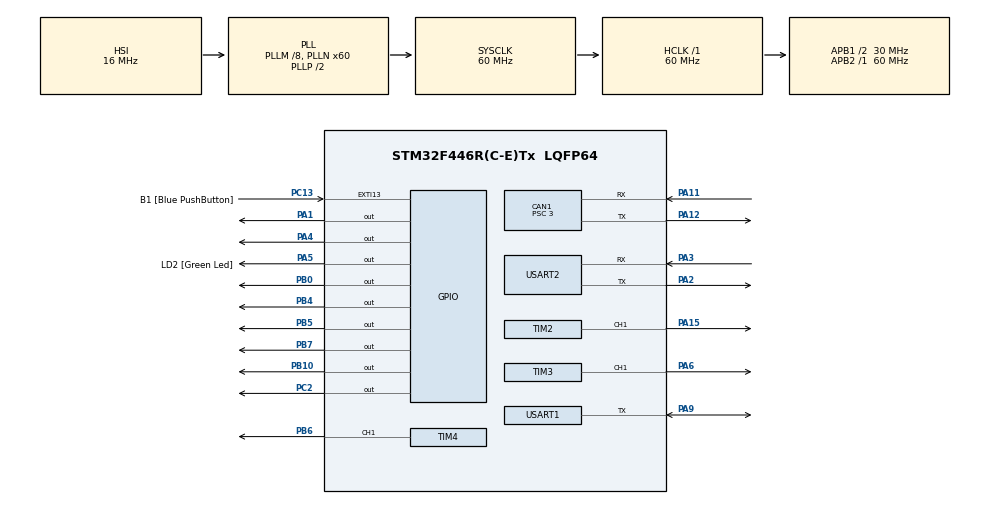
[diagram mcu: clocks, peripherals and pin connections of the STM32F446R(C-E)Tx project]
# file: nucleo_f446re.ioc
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CAN1.BS1=CAN_BS1_7TQ
CAN1.BS2=CAN_BS2_2TQ
CAN1.CalculateBaudRate=1000000
CAN1.CalculateTimeBit=1000
CAN1.CalculateTimeQuantum=100.0
CAN1.Prescaler=3
Mcu.Family=STM32F4
Mcu.Name=STM32F446R(C-E)Tx
Mcu.Package=LQFP64
NVIC.CAN1_RX0_IRQn=true\:0\:0\:false\:false\:true\:true\:true\:true
NVIC.PriorityGroup=NVIC_PRIORITYGROUP_0
NVIC.TIM2_IRQn=true\:0\:0\:false\:false\:true\:true\:true\:true
NVIC.TIM3_IRQn=true\:0\:0\:false\:false\:true\:true\:true\:true
NVIC.TIM4_IRQn=true\:0\:0\:false\:false\:true\:true\:true\:true
NVIC.TIM6_DAC_IRQn=true\:0\:0\:false\:false\:true\:true\:true\:true
NVIC.TIM7_IRQn=true\:0\:0\:false\:false\:true\:true\:true\:true
NVIC.USART1_IRQn=true\:0\:0\:false\:false\:true\:true\:true\:true
NVIC.USART2_IRQn=true\:0\:0\:false\:false\:true\:true\:true\:true
PA1.Signal=GPIO_Output
PA11.Mode=CAN_Activate
PA11.Signal=CAN1_RX
PA12.Mode=CAN_Activate
PA12.Signal=CAN1_TX
PA13.GPIO_Label=TMS
PA13.Mode=Serial_Wire
PA13.Signal=SYS_JTMS-SWDIO
PA14.GPIO_Label=TCK
PA14.Mode=Serial_Wire
PA14.Signal=SYS_JTCK-SWCLK
PA15.Signal=S_TIM2_CH1_ETR
PA2.GPIO_ModeDefaultPP=GPIO_MODE_AF_PP
PA2.GPIO_PuPd=GPIO_NOPULL
PA2.GPIO_Speed=GPIO_SPEED_FREQ_VERY_HIGH
PA2.Mode=Asynchronous
PA2.Signal=USART2_TX
PA3.GPIO_ModeDefaultPP=GPIO_MODE_AF_PP
PA3.GPIO_PuPd=GPIO_NOPULL
PA3.GPIO_Speed=GPIO_SPEED_FREQ_VERY_HIGH
PA3.Mode=Asynchronous
PA3.Signal=USART2_RX
PA4.Signal=GPIO_Output
PA5.GPIO_Label=LD2 [Green Led]
PA5.Signal=GPIO_Output
PA6.Signal=S_TIM3_CH1
PA9.GPIO_ModeDefaultOD=GPIO_MODE_AF_PP
PA9.GPIO_PuPd=GPIO_PULLUP
PA9.Mode=Half_duplex(single_wire_mode)
PA9.Signal=USART1_TX
PB0.Signal=GPIO_Output
PB10.Signal=GPIO_Output
PB3.GPIO_Label=SWO
PB3.Signal=SYS_JTDO-SWO
PB4.Signal=GPIO_Output
PB5.Signal=GPIO_Output
PB6.Signal=S_TIM4_CH1
PB7.Signal=GPIO_Output
PC13.GPIO_Label=B1 [Blue PushButton]
PC13.GPIO_ModeDefaultEXTI=GPIO_MODE_IT_FALLING
PC13.Signal=GPXTI13
PC14-OSC32_IN.Mode=LSE-External-Oscillator
PC14-OSC32_IN.Signal=RCC_OSC32_IN
PC15-OSC32_OUT.Mode=LSE-External-Oscillator
PC15-OSC32_OUT.Signal=RCC_OSC32_OUT
PC2.Signal=GPIO_Output
PH0-OSC_IN.Mode=HSE-External-Oscillator
PH0-OSC_IN.Signal=RCC_OSC_IN
PH1-OSC_OUT.Mode=HSE-External-Oscillator
PH1-OSC_OUT.Signal=RCC_OSC_OUT
ProjectManager.HeapSize=0x200
ProjectManager.StackSize=0x400
ProjectManager.TargetToolchain=Makefile
RCC.48MHZClocksFreq_Value=84000000
RCC.AHBFreq_Value=60000000
RCC.APB1CLKDivider=RCC_HCLK_DIV2
RCC.APB1Freq_Value=30000000
RCC.APB1TimFreq_Value=60000000
RCC.APB2Freq_Value=60000000
RCC.APB2TimFreq_Value=60000000
RCC.CortexFreq_Value=60000000
RCC.FLatency-AdvancedSettings=FLASH_LATENCY_1
RCC.HCLKFreq_Value=60000000
RCC.HSE_VALUE=8000000
RCC.HSI_VALUE=16000000
RCC.PLLM=8
RCC.PLLN=60
RCC.SYSCLKFreq_VALUE=60000000
RCC.SYSCLKSource=RCC_SYSCLKSOURCE_PLLCLK
RCC.USBFreq_Value=60000000
RCC.VCOOutputFreq_Value=120000000
SH.S_TIM2_CH1_ETR.0=TIM2_CH1,PWM Generation1 CH1
SH.S_TIM3_CH1.0=TIM3_CH1,PWM Generation1 CH1
SH.S_TIM4_CH1.0=TIM4_CH1,PWM Generation1 CH1
TIM2.Channel-PWM\ Generation1\ CH1=TIM_CHANNEL_1
TIM2.Period=999
TIM2.Prescaler=59
TIM2.Pulse-PWM\ Generation1\ CH1=500
TIM3.Channel-PWM\ Generation1\ CH1=TIM_CHANNEL_1
TIM3.Period=999
TIM3.Prescaler=59
TIM3.Pulse-PWM\ Generation1\ CH1=500
TIM4.Channel-PWM\ Generation1\ CH1=TIM_CHANNEL_1
TIM4.Period=999
TIM4.Prescaler=59
TIM4.Pulse-PWM\ Generation1\ CH1=500
TIM6.Period=999
TIM6.Prescaler=59
TIM7.Period=19999
TIM7.Prescaler=59
USART1.BaudRate=1000000
USART1.VirtualMode=VM_ASYNC
USART2.VirtualMode=VM_ASYNC
VP_TIM6_VS_ClockSourceINT.Mode=Enable_Timer
VP_TIM7_VS_ClockSourceINT.Mode=Enable_Timer
board=NUCLEO-F446RE

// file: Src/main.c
/* USER CODE BEGIN Header */
/**
  ******************************************************************************
  * @file           : main.c
  * @brief          : Main program body
  ******************************************************************************
  * @attention
  *
  * Copyright (c) 2026 STMicroelectronics.
  * All rights reserved.
  *
  * This software is licensed under terms that can be found in the LICENSE file
  * in the root directory of this software component.
  * If no LICENSE file comes with this software, it is provided AS-IS.
  *
  ******************************************************************************
  */
/* USER CODE END Header */
#include "main.h"
#include "can.h"
#include "tim.h"
#include "usart.h"
#include "gpio.h"

/* USER CODE BEGIN Includes */
#include <stdio.h>
/* USER CODE END Includes */

void SystemClock_Config(void);
/* USER CODE BEGIN PFP */
void setup_c(void);
void loop_c(void);
/* USER CODE END PFP */

int main(void)
{

  /* USER CODE BEGIN 1 */
  setbuf(stdout, NULL);
  /* USER CODE END 1 */

  /* MCU Configuration--------------------------------------------------------*/

  /* Reset of all peripherals, Initializes the Flash interface and the Systick. */
  HAL_Init();

  /* Configure the system clock */
  SystemClock_Config();

  /* Initialize all configured peripherals */
  MX_GPIO_Init();
  MX_CAN1_Init();
  MX_USART2_UART_Init();
  MX_USART1_UART_Init();
  MX_TIM6_Init();
  MX_TIM2_Init();
  MX_TIM4_Init();
  MX_TIM3_Init();
  MX_TIM7_Init();
  /* USER CODE BEGIN 2 */
  setup_c();
  /* USER CODE END 2 */

  /* Infinite loop */
  /* USER CODE BEGIN WHILE */
  while (1)
  {
    loop_c();
    /* USER CODE END WHILE */

  }
}

void SystemClock_Config(void)
{
  RCC_OscInitTypeDef RCC_OscInitStruct = {0};
  RCC_ClkInitTypeDef RCC_ClkInitStruct = {0};

  /** Configure the main internal regulator output voltage
  */
  __HAL_RCC_PWR_CLK_ENABLE();
  __HAL_PWR_VOLTAGESCALING_CONFIG(PWR_REGULATOR_VOLTAGE_SCALE3);

  /** Initializes the RCC Oscillators according to the specified parameters
  * in the RCC_OscInitTypeDef structure.
  */
  RCC_OscInitStruct.OscillatorType = RCC_OSCILLATORTYPE_HSI;
  RCC_OscInitStruct.HSIState = RCC_HSI_ON;
  RCC_OscInitStruct.HSICalibrationValue = RCC_HSICALIBRATION_DEFAULT;
  RCC_OscInitStruct.PLL.PLLState = RCC_PLL_ON;
  RCC_OscInitStruct.PLL.PLLSource = RCC_PLLSOURCE_HSI;
  RCC_OscInitStruct.PLL.PLLM = 8;
  RCC_OscInitStruct.PLL.PLLN = 60;
  RCC_OscInitStruct.PLL.PLLP = RCC_PLLP_DIV2;
  RCC_OscInitStruct.PLL.PLLQ = 2;
  RCC_OscInitStruct.PLL.PLLR = 2;
  if (HAL_RCC_OscConfig(&RCC_OscInitStruct) != HAL_OK)
  {
    Error_Handler();
  }

  /** Initializes the CPU, AHB and APB buses clocks
  */
  RCC_ClkInitStruct.ClockType = RCC_CLOCKTYPE_HCLK|RCC_CLOCKTYPE_SYSCLK
                              |RCC_CLOCKTYPE_PCLK1|RCC_CLOCKTYPE_PCLK2;
  RCC_ClkInitStruct.SYSCLKSource = RCC_SYSCLKSOURCE_PLLCLK;
  RCC_ClkInitStruct.AHBCLKDivider = RCC_SYSCLK_DIV1;
  RCC_ClkInitStruct.APB1CLKDivider = RCC_HCLK_DIV2;
  RCC_ClkInitStruct.APB2CLKDivider = RCC_HCLK_DIV1;

  if (HAL_RCC_ClockConfig(&RCC_ClkInitStruct, FLASH_LATENCY_1) != HAL_OK)
  {
    Error_Handler();
  }
}

/* USER CODE BEGIN 4 */
int _write(int file, char *ptr, int len)
{
  HAL_UART_Transmit(&huart2,(uint8_t *)ptr,len,HAL_MAX_DELAY);
  return len;
}
/* USER CODE END 4 */

void Error_Handler(void)
{
  __disable_irq();
  while (1)
  {
  }
}
